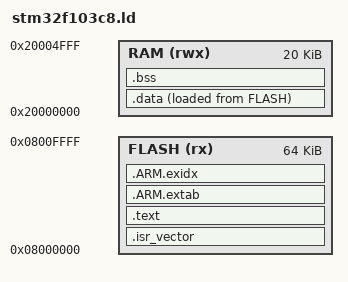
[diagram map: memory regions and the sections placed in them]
ENTRY(Reset_Handler)
MEMORY {
    FLASH (rx) : ORIGIN = 0x08000000, LENGTH = 64K
    RAM (rwx) : ORIGIN = 0x20000000, LENGTH = 20K
}
SECTIONS {
    .isr_vector : { KEEP(*(RESET)) } > FLASH
    .text : { *(.text*) *(.rodata*) . = ALIGN(4); } > FLASH
    .ARM.extab : { *(.ARM.extab*) } > FLASH
    .ARM.exidx : { *(.ARM.exidx*) } > FLASH
    .data : {
        . = ALIGN(4); _sdata = .; *(.data*) . = ALIGN(4); _edata = .;
    } > RAM AT > FLASH
    _sidata = LOADADDR(.data);
    .bss (NOLOAD) : {
        . = ALIGN(4); _sbss = .; *(.bss*) *(COMMON) . = ALIGN(4); _ebss = .;
    } > RAM
    _end = .;
    ASSERT(_end <= ORIGIN(RAM) + LENGTH(RAM) - 1024, "RAM overflow: reserve 1KB stack")
    /DISCARD/ : { *(.comment*) *(.note*) }
}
